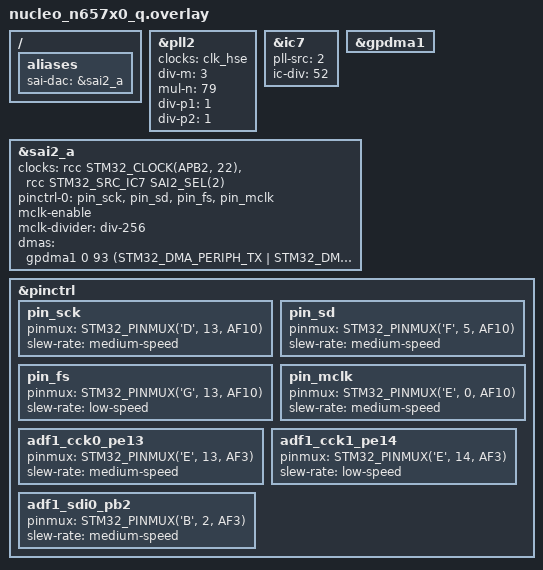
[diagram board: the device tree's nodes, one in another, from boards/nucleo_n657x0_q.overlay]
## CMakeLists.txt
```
# SPDX-License-Identifier: Apache-2.0
cmake_minimum_required(VERSION 3.20.0)
find_package(Zephyr REQUIRED HINTS $ENV{ZEPHYR_BASE})
project(pmod_i2s)

target_sources(app PRIVATE
	src/main.c
	src/adf_pdm.c
	src/pmod_i2s.c
)
```

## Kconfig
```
# App-level Kconfig for zephyr-i2s
mainmenu "zephyr-i2s configuration"

config APP_USE_ADF_PDM
	bool "Enable ADF1 PDM microphone via STM32 HAL MDF + GPIO"
	default y
	select USE_STM32_HAL_MDF
	select USE_STM32_HAL_GPIO
	help
	  Enables USE_STM32_HAL_MDF and USE_STM32_HAL_GPIO for the STM32N6
	  ADF1 PDM microphone (no native Zephyr ADF driver exists yet).

config APP_AUDIO_DIAG
	bool "Enable periodic audio pipeline diagnostics"
	default n
	help
	  Prints DMA transfer count, I2S block count, error counters,
	  and throughput (Hz) every ~10 seconds. Disable for production
	  to save code size and CPU cycles.

source "Kconfig.zephyr"
```

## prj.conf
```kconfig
# prj.conf – Zephyr-owned SAI + Zephyr DMA ADF path

CONFIG_MAIN_STACK_SIZE=4096
CONFIG_HEAP_MEM_POOL_SIZE=8192

CONFIG_PRINTK=y
CONFIG_LOG=y
CONFIG_LOG_DEFAULT_LEVEL=2
CONFIG_LOG_MODE_IMMEDIATE=y
CONFIG_ASSERT=y
CONFIG_FAULT_DUMP=2

# Zephyr-owned SAI/I2S + GPDMA path
CONFIG_I2S=y
CONFIG_DMA=y
CONFIG_DMA_STM32U5=y

# ADF1 HAL MDF + HAL GPIO (no native Zephyr ADF driver)
CONFIG_APP_USE_ADF_PDM=y

CONFIG_GPIO=y
CONFIG_CLOCK_CONTROL=y
CONFIG_CLOCK_CONTROL_STM32_CUBE=y
CONFIG_PINCTRL=y
CONFIG_ISR_STACK_SIZE=2048
CONFIG_FPU=y

CONFIG_PM=n
CONFIG_APP_AUDIO_DIAG=n
```

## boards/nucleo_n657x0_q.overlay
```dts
/*
 * Corrected Zephyr-owned SAI + GPDMA overlay for:
 *   ADF via Zephyr DMA in main.c
 *   SAI2_A via Zephyr I2S/SAI driver
 *
 * Keeps the proven clock tree and pinctrl from the user's working setup.
 *
 * DMA request IDs from RM0486:
 *   93  = sai2_a_dma
 *   94  = sai2_b_dma
 *   131 = adf1_flt0_dma (used in main.c via dma_slot)
 */

/ {
	aliases {
		sai-dac = &sai2_a;
	};
};

&pll2 {
	clocks = <&clk_hse>;
	div-m = <3>;
	mul-n = <79>;
	div-p1 = <1>;
	div-p2 = <1>;
	status = "okay";
};

&ic7 {
	pll-src = <2>;
	ic-div = <52>;
	status = "okay";
};

&gpdma1 {
	status = "okay";
};

&sai2_a {
	clocks = <&rcc STM32_CLOCK(APB2, 22)>,
		 <&rcc STM32_SRC_IC7 SAI2_SEL(2)>;
	pinctrl-0 = <&pin_sck &pin_sd &pin_fs &pin_mclk>;
	pinctrl-names = "default";
	status = "okay";
	mclk-enable;
	mclk-divider = "div-256";

	/* format: <&gpdma1 channel request channel-config> */
	dmas = <&gpdma1 0 93 (STM32_DMA_PERIPH_TX | STM32_DMA_PRIORITY_HIGH)>;
	dma-names = "tx";
};

&pinctrl {
	pin_sck: pin_sck {
		pinmux = <STM32_PINMUX('D', 13, AF10)>;
		slew-rate = "medium-speed";
	};
	pin_sd: pin_sd {
		pinmux = <STM32_PINMUX('F', 5, AF10)>;
		slew-rate = "medium-speed";
	};
	pin_fs: pin_fs {
		pinmux = <STM32_PINMUX('G', 13, AF10)>;
		slew-rate = "low-speed";
	};
	pin_mclk: pin_mclk {
		pinmux = <STM32_PINMUX('E', 0, AF10)>;
		slew-rate = "medium-speed";
	};

	adf1_cck0_pe13: adf1_cck0_pe13 {
		pinmux = <STM32_PINMUX('E', 13, AF3)>;
		slew-rate = "medium-speed";
	};
	adf1_cck1_pe14: adf1_cck1_pe14 {
		pinmux = <STM32_PINMUX('E', 14, AF3)>;
		slew-rate = "low-speed";
	};
	adf1_sdi0_pb2: adf1_sdi0_pb2 {
		pinmux = <STM32_PINMUX('B', 2, AF3)>;
		slew-rate = "medium-speed";
	};
};
```

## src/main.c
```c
/*
 * PDM mic (ADF1 DMA) -> PMOD I2S2 (SAI2_A) passthrough
 * NUCLEO-N657X0-Q  —  Zephyr v4.3+
 */

#include <zephyr/kernel.h>
#include <zephyr/logging/log.h>

#include "adf_pdm.h"
#include "pmod_i2s.h"

LOG_MODULE_REGISTER(main, LOG_LEVEL_INF);

static int32_t pcm_buf[ADF_BLOCK_SAMPLES];

int main(void)
{
	int ret;

	/* ADF PDM microphone */
	ret = adf_pdm_init();
	if (ret < 0) { LOG_ERR("adf_pdm_init: %d", ret); return 0; }

	ret = adf_pdm_start();
	if (ret < 0) { LOG_ERR("adf_pdm_start: %d", ret); return 0; }

	/* Wait for initial ADF DMA fill */
	uint32_t t0 = k_uptime_get_32();
	while (adf_pdm_available() < ADF_BLOCK_SAMPLES * PMOD_PREFILL_BLOCKS) {
		if (k_uptime_get_32() - t0 > 2000) {
			LOG_ERR("ADF DMA timeout");
			while (1) k_sleep(K_SECONDS(1));
		}
		k_sleep(K_MSEC(1));
	}
	LOG_INF("ADF ready (%u ms)", (unsigned)(k_uptime_get_32() - t0));

	/* PMOD I2S audio output */
	ret = pmod_i2s_init();
	if (ret < 0) { LOG_ERR("pmod_i2s_init: %d", ret); return 0; }

	ret = pmod_i2s_start();
	if (ret < 0) { LOG_ERR("pmod_i2s_start: %d", ret); return 0; }

	LOG_INF("PDM mic -> I2S passthrough running");

	/* Main loop */
#ifdef CONFIG_APP_AUDIO_DIAG
	uint32_t tick = 0;
#endif
	while (1) {
		ret = adf_pdm_read(pcm_buf, ADF_BLOCK_SAMPLES, K_MSEC(50));
		if (ret == 0)
			pmod_i2s_write_mono32(pcm_buf, ADF_BLOCK_SAMPLES);

#ifdef CONFIG_APP_AUDIO_DIAG
		if (++tick >= 500) {
			tick = 0;
			struct adf_pdm_stats  ast;
			struct pmod_i2s_stats ist;
			adf_pdm_get_stats(&ast);
			pmod_i2s_get_stats(&ist);
			uint32_t now = k_uptime_get_32();
			LOG_INF("adf: tc=%u err=%u | i2s: blk=%u rec=%u | %uHz",
				ast.dma_tc_count, ast.dma_restart_err,
				ist.block_count, ist.recover_count,
				now > 0 ? ist.block_count * 1000 / now : 0);
		}
#endif
	}
}
```

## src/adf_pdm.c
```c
/* adf_pdm.c — STM32N6 ADF PDM microphone driver implementation */

#include "adf_pdm.h"

#include <zephyr/device.h>
#include <zephyr/drivers/dma.h>
#include <zephyr/logging/log.h>
#include <string.h>

#include <stm32n6xx_hal.h>
#include <stm32n6xx_ll_rcc.h>

LOG_MODULE_REGISTER(adf_pdm, LOG_LEVEL_INF);

/* ---- Private state ------------------------------------------------------ */

static int32_t dma_buf[ADF_BLOCK_SAMPLES] __attribute__((aligned(32)));
static int32_t ring[ADF_RING_SIZE];

static volatile uint32_t ring_wr;
static volatile uint32_t ring_rd;

static K_SEM_DEFINE(data_ready, 0, 1);

static volatile uint32_t tc_count;
static volatile uint32_t restart_err;

static const struct device *dma_dev;
static struct dma_config    dma_cfg;
static struct dma_block_config dma_blk;
static uint32_t src_addr;

static MDF_HandleTypeDef hadf;

/* ---- Ring buffer -------------------------------------------------------- */

static void ring_push(const int32_t *src, uint32_t count)
{
	uint32_t wr = ring_wr;

	for (uint32_t i = 0; i < count; i++) {
		ring[wr] = src[i];
		wr = (wr + 1U) % ADF_RING_SIZE;
	}
	ring_wr = wr;
}

uint32_t adf_pdm_available(void)
{
	return (ring_wr - ring_rd + ADF_RING_SIZE) % ADF_RING_SIZE;
}

/* ---- DMA callback ------------------------------------------------------- */

static void dma_cb(const struct device *dev, void *user_data,
		    uint32_t channel, int status)
{
	ARG_UNUSED(user_data);

	if (status < 0) {
		restart_err++;
		return;
	}

	tc_count++;
	SCB_InvalidateDCache_by_Addr((void *)dma_buf,
				     ADF_BLOCK_SAMPLES * sizeof(int32_t));
	ring_push(dma_buf, ADF_BLOCK_SAMPLES);

	if (adf_pdm_available() >= ADF_BLOCK_SAMPLES)
		k_sem_give(&data_ready);

	if (dma_reload(dev, channel, src_addr, (uint32_t)dma_buf,
		       ADF_BLOCK_SAMPLES * sizeof(int32_t)) < 0 ||
	    dma_start(dev, channel) < 0)
		restart_err++;
}

/* ---- Init --------------------------------------------------------------- */

int adf_pdm_init(void)
{
	/* Clocks */
	__HAL_RCC_ADF1_CLK_ENABLE();
	__HAL_RCC_GPIOB_CLK_ENABLE();
	__HAL_RCC_GPIOE_CLK_ENABLE();
#ifdef __HAL_RCC_ADF1_CLK_SLEEP_ENABLE
	__HAL_RCC_ADF1_CLK_SLEEP_ENABLE();
#endif
	SCB->SCR &= ~SCB_SCR_SLEEPDEEP_Msk;
	LL_RCC_SetADFClockSource(LL_RCC_ADF1_CLKSOURCE_IC7);

	uint32_t clk = HAL_RCCEx_GetPeriphCLKFreq(RCC_PERIPHCLK_ADF1);
	LOG_INF("ADF1 clock: %u Hz, CCK0=%.3f MHz, PCM=%u Hz",
		(unsigned)clk,
		(double)clk / ADF_CCK_DIVIDER / 1e6,
		(unsigned)(clk / ADF_CCK_DIVIDER / 64U));

	/* GPIO */
	GPIO_InitTypeDef gpio = {
		.Mode      = GPIO_MODE_AF_PP,
		.Pull      = GPIO_NOPULL,
		.Alternate = ADF_GPIO_AF,
	};

	gpio.Pin = ADF_CCK0_PIN; gpio.Speed = ADF_CCK0_SPEED;
	HAL_GPIO_Init(ADF_CCK0_PORT, &gpio);

	gpio.Pin = ADF_CCK1_PIN; gpio.Speed = ADF_CCK1_SPEED;
	HAL_GPIO_Init(ADF_CCK1_PORT, &gpio);

	gpio.Pin = ADF_SDI0_PIN; gpio.Speed = ADF_SDI0_SPEED;
	HAL_GPIO_Init(ADF_SDI0_PORT, &gpio);

	/* HAL MDF: serial interface + output clock */
	hadf.Instance = ADF1_Filter0;
	hadf.hdma     = NULL;

	hadf.Init.CommonParam.InterleavedFilters             = 0U;
	hadf.Init.CommonParam.ProcClockDivider               = 1U;
	hadf.Init.CommonParam.OutputClock.Activation         = ENABLE;
	hadf.Init.CommonParam.OutputClock.Pins               = MDF_OUTPUT_CLOCK_0;
	hadf.Init.CommonParam.OutputClock.Divider            = ADF_CCK_DIVIDER;
	hadf.Init.CommonParam.OutputClock.Trigger.Activation = DISABLE;
	hadf.Init.CommonParam.OutputClock.Trigger.Source      = MDF_CLOCK_TRIG_TRGO;
	hadf.Init.CommonParam.OutputClock.Trigger.Edge       = MDF_CLOCK_TRIG_RISING_EDGE;

	hadf.Init.SerialInterface.Activation  = ENABLE;
	hadf.Init.SerialInterface.Mode        = MDF_SITF_NORMAL_SPI_MODE;
	hadf.Init.SerialInterface.ClockSource = MDF_SITF_CCK0_SOURCE;
	hadf.Init.SerialInterface.Threshold   = 31U;
	hadf.Init.FilterBistream              = MDF_BITSTREAM0_RISING;

	if (HAL_MDF_Init(&hadf) != HAL_OK) {
		LOG_ERR("HAL_MDF_Init failed");
		return -EIO;
	}

	LOG_INF("ADF1 init OK");
	return 0;
}

/* ---- DMA setup ---------------------------------------------------------- */

static int dma_setup(void)
{
	dma_dev = DEVICE_DT_GET(DT_NODELABEL(gpdma1));
	if (!device_is_ready(dma_dev)) {
		LOG_ERR("GPDMA1 not ready");
		return -ENODEV;
	}

	MDF_Filter_TypeDef *f = (MDF_Filter_TypeDef *)hadf.Instance;
	src_addr = (uint32_t)&f->DFLTDR;

	memset(&dma_blk, 0, sizeof(dma_blk));
	dma_blk.source_address  = src_addr;
	dma_blk.dest_address    = (uint32_t)dma_buf;
	dma_blk.block_size      = ADF_BLOCK_SAMPLES * sizeof(int32_t);
	dma_blk.source_addr_adj = DMA_ADDR_ADJ_NO_CHANGE;
	dma_blk.dest_addr_adj   = DMA_ADDR_ADJ_INCREMENT;

	memset(&dma_cfg, 0, sizeof(dma_cfg));
	dma_cfg.dma_slot            = GPDMA1_REQUEST_ADF1_FLT0;
	dma_cfg.channel_direction   = PERIPHERAL_TO_MEMORY;
	dma_cfg.complete_callback_en = 1;
	dma_cfg.source_data_size    = 4;
	dma_cfg.dest_data_size      = 4;
	dma_cfg.source_burst_length = 1;
	dma_cfg.dest_burst_length   = 1;
	dma_cfg.block_count         = 1;
	dma_cfg.head_block          = &dma_blk;
	dma_cfg.dma_callback        = dma_cb;

	int ret = dma_config(dma_dev, ADF_DMA_CHANNEL, &dma_cfg);
	if (ret < 0) {
		LOG_ERR("dma_config ch%d failed: %d", ADF_DMA_CHANNEL, ret);
		return ret;
	}

	LOG_INF("DMA ch%d configured (slot=%u, %u bytes/xfer)",
		ADF_DMA_CHANNEL, (unsigned)dma_cfg.dma_slot,
		(unsigned)dma_blk.block_size);
	return 0;
}

/* ---- Start -------------------------------------------------------------- */

int adf_pdm_start(void)
{
	MDF_Filter_TypeDef *f = (MDF_Filter_TypeDef *)hadf.Instance;
	int ret;

	f->DFLTCR   &= ~MDF_DFLTCR_DFLTEN;
	f->DFLTCICR  = ADF_DFLTCICR_VAL;
	f->DFLTRSFR  = ADF_DFLTRSFR_VAL;
	f->DFLTIER   = 0U;
	f->DFLTCR    = MDF_DFLTCR_DMAEN | MDF_DFLTCR_FTH;

	ret = dma_setup();
	if (ret < 0)
		return ret;

	ret = dma_start(dma_dev, ADF_DMA_CHANNEL);
	if (ret < 0) {
		LOG_ERR("dma_start failed: %d", ret);
		return ret;
	}

	SET_BIT(f->DFLTCR, MDF_DFLTCR_DFLTEN);
	hadf.State = HAL_MDF_STATE_ACQUISITION;

	LOG_INF("ADF1 DMA started (CICR=0x%08x RSFR=0x%08x CR=0x%08x)",
		(unsigned)f->DFLTCICR, (unsigned)f->DFLTRSFR,
		(unsigned)f->DFLTCR);
	return 0;
}

/* ---- Read --------------------------------------------------------------- */

int adf_pdm_read(int32_t *buf, uint32_t count, k_timeout_t timeout)
{
	while (adf_pdm_available() < count) {
		if (k_sem_take(&data_ready, timeout) != 0)
			return -EAGAIN;
	}

	uint32_t rd = ring_rd;
	for (uint32_t i = 0; i < count; i++) {
		buf[i] = ring[rd];
		rd = (rd + 1U) % ADF_RING_SIZE;
	}
	ring_rd = rd;
	return 0;
}

/* ---- Stats -------------------------------------------------------------- */

void adf_pdm_get_stats(struct adf_pdm_stats *stats)
{
	stats->dma_tc_count    = tc_count;
	stats->dma_restart_err = restart_err;
}
```

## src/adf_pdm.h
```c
/*
 * adf_pdm.h — STM32N6 ADF PDM microphone driver (Zephyr DMA)
 *
 * All definitions, register macros, data structures, and declarations
 * live here. The .c file contains only implementation.
 */

#ifndef ADF_PDM_H
#define ADF_PDM_H

#include <zephyr/kernel.h>
#include <stm32n6xx_hal_mdf.h>
#include <stdint.h>
#include <stdbool.h>

/*
 * Clock configuration
 *
 * IC7 is routed to ADF1 via LL_RCC.  CCK0 = IC7 / ADF_CCK_DIVIDER.
 * PCM sample rate = CCK0 / (ADF_DEC_RATIO * ADF_RSF_DEC_RATIO).
 */
#define ADF_CCK_DIVIDER		8

/*
 * CIC filter parameters
 *
 * These compose into the DFLTCICR register at compile time.
 * Golden value verified against HAL: DFLTCICR = 0x00200f50
 */
#define ADF_CIC_MODE		MDF_ONE_FILTER_SINC5
#define ADF_DATA_SRC		MDF_DATA_SOURCE_BSMX
#define ADF_DEC_RATIO		16	/* CIC decimation ratio, 1–256 */
#define ADF_GAIN		2	/* output scale, 0–15 */
#define ADF_DELAY		0	/* data delay in CCK cycles, 0–127 */

/* 
 * Reshape filter
 *
 * Bypass bit is inverted logic: 0 = enabled, 1 = bypassed.
 */
#define ADF_RSF_ENABLE		1
#define ADF_RSF_DEC		MDF_RSF_DECIMATION_RATIO_4

/* 
 * High-pass filter
 *
 * Bypass bit is inverted logic: 0 = enabled, 1 = bypassed.
 */
#define ADF_HPF_ENABLE		1
#define ADF_HPF_CUTOFF		MDF_HPF_CUTOFF_0_000625FPCM

/* DMA / buffer sizing  */
#define ADF_DMA_CHANNEL		7	/* GPDMA1 channel (avoid SAI TX) */
#define ADF_BLOCK_SAMPLES	960	/* samples per DMA transfer */
#define ADF_RING_BLOCKS		8	/* ring buffer depth in blocks */
#define ADF_RING_SIZE		(ADF_BLOCK_SAMPLES * ADF_RING_BLOCKS)

/*
 * GPIO pins (NUCLEO-N657X0-Q)
 *
 * PE13 = CCK0 (output clock to mic)
 * PE14 = CCK1 (unused, configured for completeness)
 * PB2  = SDI0 (PDM data input)
 */
#define ADF_CCK0_PORT		GPIOE
#define ADF_CCK0_PIN		GPIO_PIN_13
#define ADF_CCK0_SPEED		GPIO_SPEED_FREQ_MEDIUM

#define ADF_CCK1_PORT		GPIOE
#define ADF_CCK1_PIN		GPIO_PIN_14
#define ADF_CCK1_SPEED		GPIO_SPEED_FREQ_LOW

#define ADF_SDI0_PORT		GPIOB
#define ADF_SDI0_PIN		GPIO_PIN_2
#define ADF_SDI0_SPEED		GPIO_SPEED_FREQ_MEDIUM

#define ADF_GPIO_AF		GPIO_AF3_ADF1

/*
 * Register composition (compile-time)
 *
 * DFLTCICR:
 *   [3:0]   data source  (HAL pre-shifted)
 *   [6:4]   CIC mode     (HAL pre-shifted)
 *   [15:8]  dec ratio - 1
 *   [22:16] delay
 *   [23:20] gain/scale
 *
 * DFLTRSFR:
 *   bit 0   reshape bypass  (0=enabled, 1=bypassed)
 *   [6:4]   reshape dec     (HAL pre-shifted)
 *   bit 7   HPF bypass      (0=enabled, 1=bypassed)
 *   [10:8]  HPF cutoff      (HAL pre-shifted)
 */
#define ADF_DFLTCICR_VAL	(ADF_DATA_SRC | ADF_CIC_MODE | \
				 (((ADF_DEC_RATIO) - 1U) << 8) | \
				 ((uint32_t)(ADF_GAIN) << 20) | \
				 ((uint32_t)(ADF_DELAY) << 16))

#define ADF_RSF_BYP		((ADF_RSF_ENABLE) ? 0U : (1UL << 0))
#define ADF_HPF_BYP		((ADF_HPF_ENABLE) ? 0U : (1UL << 7))
#define ADF_DFLTRSFR_VAL	(ADF_RSF_BYP | ADF_RSF_DEC | \
				 ADF_HPF_BYP | ADF_HPF_CUTOFF)

/* DFLTCR bit definitions (fallbacks if CMSIS headers lack them) */
#ifndef MDF_DFLTCR_DFLTEN
#define MDF_DFLTCR_DFLTEN	(1UL << 0)
#endif
#ifndef MDF_DFLTCR_DMAEN
#define MDF_DFLTCR_DMAEN	(1UL << 1)
#endif
#ifndef MDF_DFLTCR_FTH
#define MDF_DFLTCR_FTH		(1UL << 2)
#endif

/* Driver statistics */
struct adf_pdm_stats {
	uint32_t dma_tc_count;		/* DMA transfer-complete count */
	uint32_t dma_restart_err;	/* DMA reload/start failures */
};

/*
 * adf_pdm_init - Initialise ADF1 clocks, GPIO, and serial interface.
 *
 * Enables ADF1/GPIO RCC clocks, configures PDM pins, routes IC7 to ADF1
 * clock mux, and calls HAL_MDF_Init for serial interface + output clock.
 *
 * Return: 0 on success, negative errno on failure.
 */
int adf_pdm_init(void);

/*
 * adf_pdm_start - Configure filter and start DMA acquisition.
 *
 * Writes DFLTCICR/DFLTRSFR directly (composed from defines above),
 * sets DMAEN, starts Zephyr DMA, then enables the filter.
 * Must be called after adf_pdm_init().
 *
 * Return: 0 on success, negative errno on failure.
 */
int adf_pdm_start(void);

/*
 * adf_pdm_read - Read PCM samples from the internal ring buffer.
 *
 * Blocks on a semaphore until @count samples are available or @timeout
 * expires. Samples are 32-bit signed, from the MDF filter output.
 *
 * @buf:     destination buffer (caller-allocated)
 * @count:   number of int32_t samples to read
 * @timeout: max wait (K_FOREVER, K_MSEC(n), K_NO_WAIT)
 *
 * Return: 0 on success, -EAGAIN on timeout.
 */
int adf_pdm_read(int32_t *buf, uint32_t count, k_timeout_t timeout);

/* adf_pdm_available - Return samples currently available in ring buffer */
uint32_t adf_pdm_available(void);

/* adf_pdm_get_stats - Copy current DMA statistics */
void adf_pdm_get_stats(struct adf_pdm_stats *stats);

#endif /* ADF_PDM_H */
```

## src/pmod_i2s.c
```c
/* pmod_i2s.c — PMOD I2S audio output driver implementation */

#include "pmod_i2s.h"

#include <zephyr/device.h>
#include <zephyr/drivers/i2s.h>
#include <zephyr/logging/log.h>
#include <string.h>

LOG_MODULE_REGISTER(pmod_i2s, LOG_LEVEL_INF);

K_MEM_SLAB_DEFINE(tx_slab, PMOD_BLOCK_SIZE_BYTES, PMOD_NUM_BLOCKS, 16);

/* ---- Private state ------------------------------------------------------ */

static const struct device *i2s_dev;
static uint32_t stat_blocks;
static uint32_t stat_recovers;

/* ---- TX recover --------------------------------------------------------- */

static int tx_recover(void)
{
	stat_recovers++;
	LOG_WRN("SAI recover #%u (block=%u)", stat_recovers, stat_blocks);

	int ret = i2s_trigger(i2s_dev, I2S_DIR_TX, I2S_TRIGGER_DROP);
	if (ret < 0) {
		LOG_ERR("I2S DROP failed: %d", ret);
		return ret;
	}

	k_sleep(K_MSEC(5));

	for (int i = 0; i < 2; i++) {
		void *blk;
		if (k_mem_slab_alloc(&tx_slab, &blk, K_MSEC(50)) < 0)
			continue;
		memset(blk, 0, PMOD_BLOCK_SIZE_BYTES);
		i2s_write(i2s_dev, blk, PMOD_BLOCK_SIZE_BYTES);
	}

	ret = i2s_trigger(i2s_dev, I2S_DIR_TX, I2S_TRIGGER_START);
	if (ret < 0)
		LOG_ERR("recover START failed: %d", ret);
	return ret;
}

/* ---- Init --------------------------------------------------------------- */

int pmod_i2s_init(void)
{
	i2s_dev = DEVICE_DT_GET(DT_ALIAS(PMOD_I2S_DT_ALIAS));
	if (!device_is_ready(i2s_dev)) {
		LOG_ERR("I2S device not ready");
		return -ENODEV;
	}

	struct i2s_config cfg = {
		.word_size      = PMOD_BIT_WIDTH,
		.channels       = PMOD_NUM_CHANNELS,
		.format         = I2S_FMT_DATA_FORMAT_I2S,
		.options        = I2S_OPT_BIT_CLK_MASTER |
				  I2S_OPT_FRAME_CLK_MASTER,
		.frame_clk_freq = PMOD_SAMPLE_RATE,
		.mem_slab       = &tx_slab,
		.block_size     = PMOD_BLOCK_SIZE_BYTES,
		.timeout        = 1000,
	};

	int ret = i2s_configure(i2s_dev, I2S_DIR_TX, &cfg);
	if (ret < 0) {
		LOG_ERR("i2s_configure failed: %d", ret);
		return ret;
	}

	/* Prefill TX queue with silence */
	for (int i = 0; i < PMOD_PREFILL_BLOCKS; i++) {
		void *blk;
		if (k_mem_slab_alloc(&tx_slab, &blk, K_FOREVER) == 0) {
			memset(blk, 0, PMOD_BLOCK_SIZE_BYTES);
			ret = i2s_write(i2s_dev, blk, PMOD_BLOCK_SIZE_BYTES);
			if (ret < 0) {
				k_mem_slab_free(&tx_slab, blk);
				LOG_ERR("prefill write failed: %d", ret);
				return ret;
			}
		}
	}

	LOG_INF("PMOD I2S init OK: %u Hz / %u-bit / %u-ch",
		PMOD_SAMPLE_RATE, PMOD_BIT_WIDTH, PMOD_NUM_CHANNELS);
	return 0;
}

/* ---- Start -------------------------------------------------------------- */

int pmod_i2s_start(void)
{
	int ret = i2s_trigger(i2s_dev, I2S_DIR_TX, I2S_TRIGGER_START);
	if (ret < 0) {
		LOG_ERR("I2S START failed: %d", ret);
		return ret;
	}
	LOG_INF("PMOD I2S TX started");
	return 0;
}

/* ---- Write -------------------------------------------------------------- */

int pmod_i2s_write_mono32(const int32_t *samples, uint32_t count)
{
	void *blk;
	int ret = k_mem_slab_alloc(&tx_slab, &blk, K_MSEC(15));
	if (ret < 0) {
		LOG_WRN("TX slab alloc failed");
		return tx_recover();
	}

	int16_t *dst = blk;
	for (uint32_t i = 0; i < count; i++) {
		int32_t s = samples[i] >> PMOD_SHIFT_BITS;
		s = (s > 32767) ? 32767 : (s < -32768) ? -32768 : s;
		*dst++ = (int16_t)s;
		*dst++ = (int16_t)s;
	}
	stat_blocks++;

	ret = i2s_write(i2s_dev, blk, PMOD_BLOCK_SIZE_BYTES);
	if (ret < 0) {
		k_mem_slab_free(&tx_slab, blk);
		if (ret == -EBUSY || ret == -EAGAIN) {
			stat_recovers++;
			return ret;
		}
		return tx_recover();
	}
	return 0;
}

/* ---- Stats -------------------------------------------------------------- */

void pmod_i2s_get_stats(struct pmod_i2s_stats *stats)
{
	stats->block_count   = stat_blocks;
	stats->recover_count = stat_recovers;
}
```

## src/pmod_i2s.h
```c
/*
 * pmod_i2s.h — PMOD I2S audio output driver (Zephyr I2S/SAI)
 *
 * All definitions, data structures, and declarations live here.
 * The .c file contains only implementation.
 */

#ifndef PMOD_I2S_H
#define PMOD_I2S_H

#include <zephyr/kernel.h>
#include <stdint.h>

/* I2S audio format */
#define PMOD_SAMPLE_RATE	48000U
#define PMOD_NUM_CHANNELS	2
#define PMOD_BIT_WIDTH		16

/* 
 * Buffer sizing
 *
 * PMOD_BLOCK_SAMPLES must match ADF_BLOCK_SAMPLES when used together.
 */
#define PMOD_BLOCK_SAMPLES	960
#define PMOD_NUM_BLOCKS		16	/* I2S TX queue depth */
#define PMOD_PREFILL_BLOCKS	4	/* silence blocks before START */

/* Derived constants */
#define PMOD_BLOCK_SIZE_BYTES	(PMOD_BLOCK_SAMPLES * PMOD_NUM_CHANNELS * \
				 (PMOD_BIT_WIDTH / 8))

/* 
 * Mono-to-stereo conversion
 *
 * Input: 32-bit signed PCM from MDF filter
 * Output: 16-bit signed stereo (L=R)
 *
 * PMOD_SHIFT_BITS: right-shift applied before clamping to int16 range.
 * Adjust to match your MDF filter gain setting.
 */
#define PMOD_SHIFT_BITS		10

/* 
 * Device tree alias
 *
 * The overlay must define: aliases { sai-dac = &sai2_a; };
 */
#define PMOD_I2S_DT_ALIAS	sai_dac

/* Driver statistics */
struct pmod_i2s_stats {
	uint32_t block_count;		/* blocks successfully written */
	uint32_t recover_count;		/* TX underrun recoveries */
};

/*
 * pmod_i2s_init - Configure I2S and prefill TX queue with silence.
 *
 * Looks up the I2S device from device tree (PMOD_I2S_DT_ALIAS),
 * configures it with the format defined above, and queues
 * PMOD_PREFILL_BLOCKS of silence so TX can start immediately.
 *
 * Return: 0 on success, negative errno on failure.
 */
int pmod_i2s_init(void);

/*
 * pmod_i2s_start - Start I2S TX stream.
 *
 * Issues I2S_TRIGGER_START.  Must be called after pmod_i2s_init().
 *
 * Return: 0 on success, negative errno on failure.
 */
int pmod_i2s_start(void);

/*
 * pmod_i2s_write_mono32 - Write mono 32-bit samples as stereo 16-bit I2S.
 *
 * For each sample: right-shift by PMOD_SHIFT_BITS, clamp to int16 range,
 * duplicate to L+R channels, write to I2S TX queue.
 * Auto-recovers on TX underrun (DROP → refill → START).
 *
 * @samples: mono 32-bit PCM input buffer
 * @count:   number of samples (should be PMOD_BLOCK_SAMPLES)
 *
 * Return: 0 on success, negative errno on failure.
 */
int pmod_i2s_write_mono32(const int32_t *samples, uint32_t count);

/* pmod_i2s_get_stats - Copy current driver statistics  */
void pmod_i2s_get_stats(struct pmod_i2s_stats *stats);

#endif /* PMOD_I2S_H */
```
